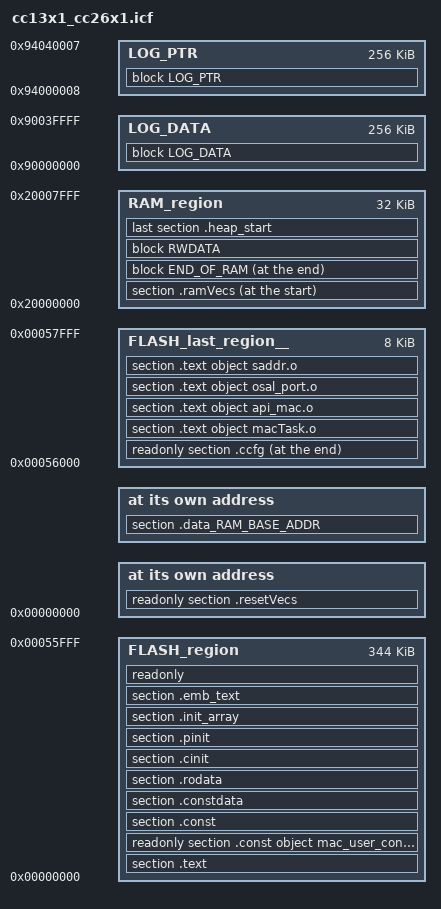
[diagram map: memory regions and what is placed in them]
/******************************************************************************

 @file  cc13x1_cc26x1.icf

 @brief Linker configuration file for sensor/collector on cc13x2/cc26x2 devices

 Group: WCS LPC
 Target Device: cc13xx_cc26xx

 ******************************************************************************
 
 Copyright (c) 2016-2025, Texas Instruments Incorporated
 All rights reserved.

 Redistribution and use in source and binary forms, with or without
 modification, are permitted provided that the following conditions
 are met:

 *  Redistributions of source code must retain the above copyright
    notice, this list of conditions and the following disclaimer.

 *  Redistributions in binary form must reproduce the above copyright
    notice, this list of conditions and the following disclaimer in the
    documentation and/or other materials provided with the distribution.

 *  Neither the name of Texas Instruments Incorporated nor the names of
    its contributors may be used to endorse or promote products derived
    from this software without specific prior written permission.

 THIS SOFTWARE IS PROVIDED BY THE COPYRIGHT HOLDERS AND CONTRIBUTORS "AS IS"
 AND ANY EXPRESS OR IMPLIED WARRANTIES, INCLUDING, BUT NOT LIMITED TO,
 THE IMPLIED WARRANTIES OF MERCHANTABILITY AND FITNESS FOR A PARTICULAR
 PURPOSE ARE DISCLAIMED. IN NO EVENT SHALL THE COPYRIGHT OWNER OR
 CONTRIBUTORS BE LIABLE FOR ANY DIRECT, INDIRECT, INCIDENTAL, SPECIAL,
 EXEMPLARY, OR CONSEQUENTIAL DAMAGES (INCLUDING, BUT NOT LIMITED TO,
 PROCUREMENT OF SUBSTITUTE GOODS OR SERVICES; LOSS OF USE, DATA, OR PROFITS;
 OR BUSINESS INTERRUPTION) HOWEVER CAUSED AND ON ANY THEORY OF LIABILITY,
 WHETHER IN CONTRACT, STRICT LIABILITY, OR TORT (INCLUDING NEGLIGENCE OR
 OTHERWISE) ARISING IN ANY WAY OUT OF THE USE OF THIS SOFTWARE,
 EVEN IF ADVISED OF THE POSSIBILITY OF SUCH DAMAGE.

 ******************************************************************************
 
 
 *****************************************************************************/

///////////////////////////////////////////////////////////////////////////////
// Memory Sizes
///////////////////////////////////////////////////////////////////////////////

/* Intvec start */
define symbol FLASH_BASE__         = 0x00000000;
define symbol FLASH_LAST_base__    = 0x00056000;
define symbol RAM_base__           = 0x20000000;

define symbol FLASH_SIZE__         = 0x56000;
define symbol FLASH_LAST_size__    = 0x00002000;
define symbol RAM_size__           = 0x8000;

///////////////////////////////////////////////////////////////////////////////
// Memory Definitions
///////////////////////////////////////////////////////////////////////////////

///////////////////////////////////////////////////////////////////////////////
// Flash
//
define symbol WORD_SIZE            = 4;
define symbol FLASH_MEM_ALIGN      = WORD_SIZE;

/* Define a memory region that covers the entire 4 GB addressable space */
define memory mem with size = 4G;

/* Memory Regions */

/* Define a region for the on-chip flash */
define region FLASH_region = mem:[from FLASH_BASE__ size FLASH_SIZE__];

/* Define a region for the last flash page */
define region FLASH_last_region__ = mem:[from FLASH_LAST_base__ size FLASH_LAST_size__];

///////////////////////////////////////////////////////////////////////////////
// RAM
//

/* Internal RAM for data used by application */
define region RAM_region = mem:[from RAM_base__ size RAM_size__];

///////////////////////////////////////////////////////////////////////////////
// Memory Placement
///////////////////////////////////////////////////////////////////////////////

///////////////////////////////////////////////////////////////////////////////
// Memory Placement in Flash
//

/* Place the interrupt vectors at the start of flash */
place at address mem:FLASH_BASE__ { readonly section .resetVecs};
keep { section .resetVecs};

/* Place the CCS area at the end of flash */
place at end of FLASH_last_region__ { readonly section .ccfg };
keep { section .ccfg };

place in FLASH_last_region__ { section .text object macTask.o };
place in FLASH_last_region__ { section .text object api_mac.o };
place in FLASH_last_region__ { section .text object osal_port.o };
place in FLASH_last_region__ { section .text object saddr.o };

place in FLASH_region { section .text };

place in FLASH_region { readonly section .const object mac_user_config.o };

place in FLASH_region { 
	section .const,
	section .constdata,
	section .rodata,
	section .cinit,
	section .pinit,
	section .init_array,
	section .emb_text
};

/* Place remaining 'read only' in Flash */
place in FLASH_region { readonly };

///////////////////////////////////////////////////////////////////////////////
// Memory Placement in RAM
//

/* Place .ramVecs in start of RAM */
place at start of RAM_region { section .ramVecs };
do not initialize { section .ramVecs };
/*
place in RAM_region  {
	section .data,
	section .bss,
	section .vtable,
	section .vtable_ram,
	section .vtable_ram,
	section .sysmem,
	section .nonretenvar,
};
*/

/*
 * Define CSTACK block to contain .stack section. This enables the IAR IDE
 * to properly show the stack content during debug. Place stack at end of
 * retention RAM, do not initialize (initializing the stack will destroy the
 * return address from the initialization code, causing the processor to branch
 * to zero and fault)
 */
define symbol STACKSIZE = 1024;
define block CSTACK with alignment = 8, size = STACKSIZE { section .stack };

//place at end of RAM_region { block CSTACK };
if (isdefinedsymbol(ROM_TIMACDataAddr)) {
    place at address mem:ROM_TIMACDataAddr {section .data_RAM_BASE_ADDR };
}

/* Export stack top symbol. Used by startup file */
define exported symbol STACK_TOP = end(RAM_region) + 1;

define block RWDATA { rw };

define section .heap_start            { public heapStart: };
define section .heap_end              { public heapEnd: };
define block   HEAP_END with size = 1 { section .heap_end };

define block END_OF_RAM with fixed order {
                                        block HEAP_END,
                                        block CSTACK
                                      };
place at end of RAM_region { block END_OF_RAM };

place in RAM_region { block RWDATA,
               last section .heap_start};


initialize by copy { readwrite };
do not initialize { section .stack, section .noinit};

/* Explicitly placed off target for the storage of logging data.
 * The data placed here is NOT  loaded ont the target device.
 * This is part of 1 GB of external memory from 0x60000000 - 0x9FFFFFFF.
 * ARM memory map can be found here:
 * https://developer.arm.com/documentation/ddi0337/e/memory-map/about-the-memory-map
 */
define region LOG_DATA = mem:[from 0x90000000 to 0x9003FFFF];
define region LOG_PTR = mem:[from 0x94000008 to 0x94040007];
define block LOG_DATA  with size = 0x40000 { readonly section .log_data  };
define block LOG_PTR   with size = 0x40000 { readonly section .log_ptr* };
".log_data": place noload in LOG_DATA { block LOG_DATA };
".log_ptr": place noload in LOG_PTR { block LOG_PTR };

///////////////////////////////////////////////////////////////////////////////
// Other Linker Directives
///////////////////////////////////////////////////////////////////////////////

/*
 * The USE_TIRTOS_ROM symbol is defined internally in the build flow (using
 * --config_def USE_TIRTOS_ROM=1) for TI-RTOS applications whose app.cfg file
 * specifies to use the ROM.
 */
if (isdefinedsymbol(USE_TIRTOS_ROM)) {
    include "TIRTOS_ROM.icf";
}
